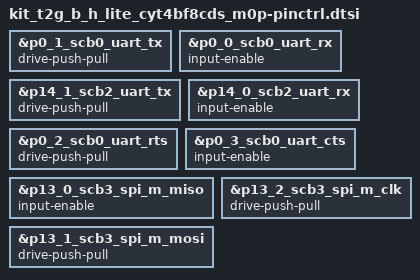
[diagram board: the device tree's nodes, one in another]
/*
 * SPDX-FileCopyrightText: <text>Copyright (c) 2026 Infineon Technologies AG,
 * or an affiliate of Infineon Technologies AG. All rights reserved.</text>
 * Copyright (c) 2026 Linumiz
 * SPDX-License-Identifier: Apache-2.0
 */

#include <arm/infineon/cat1c/traveo/cyt4bf/cyt4bf8cds.dtsi>

/* Configure pin control bias mode for uart pins */
&p0_1_scb0_uart_tx {
	drive-push-pull;
};

&p0_0_scb0_uart_rx {
	input-enable;
};

&p14_1_scb2_uart_tx {
	drive-push-pull;
};

&p14_0_scb2_uart_rx {
	input-enable;
};

&p0_2_scb0_uart_rts {
	drive-push-pull;
};

&p0_3_scb0_uart_cts {
	input-enable;
};

&p13_0_scb3_spi_m_miso {
	input-enable;
};

&p13_1_scb3_spi_m_mosi {
	drive-push-pull;
};

&p13_2_scb3_spi_m_clk {
	drive-push-pull;
};
